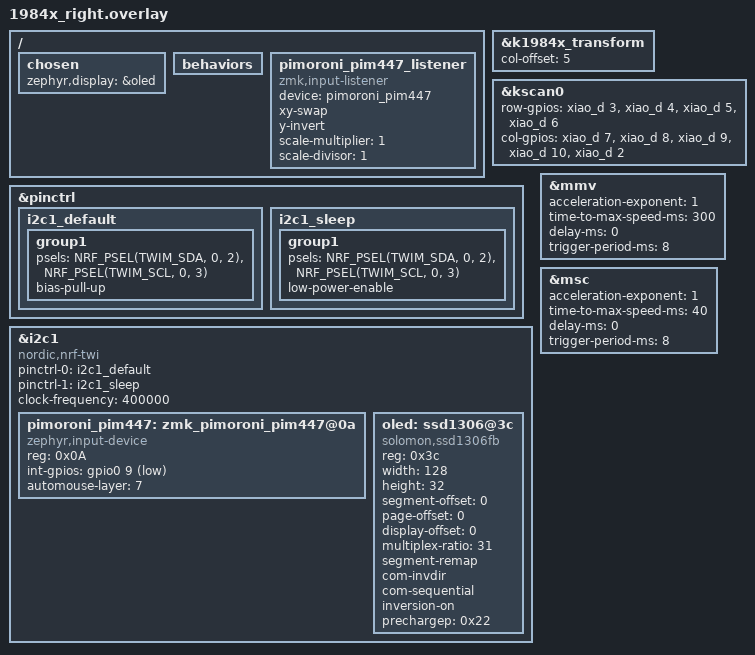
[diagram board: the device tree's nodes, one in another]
#include "1984x.dtsi"


#define ZMK_MOUSE_DEFAULT_MOVE_VAL 600  // 600
#define ZMK_MOUSE_DEFAULT_SCRL_VAL 10    // 10

#include <dt-bindings/zmk/mouse.h>

#include <behaviors/mouse_keys.dtsi>
#include <behaviors/mouse_move.dtsi>

&k1984x_transform {
    col-offset = <5>;
};

&kscan0 {
    row-gpios
        = <&xiao_d 3 (GPIO_ACTIVE_HIGH | GPIO_PULL_DOWN)>
        , <&xiao_d 4 (GPIO_ACTIVE_HIGH | GPIO_PULL_DOWN)>
        , <&xiao_d 5 (GPIO_ACTIVE_HIGH | GPIO_PULL_DOWN)>
        , <&xiao_d 6 (GPIO_ACTIVE_HIGH | GPIO_PULL_DOWN)>
        ;

    col-gpios
        = <&xiao_d 7 GPIO_ACTIVE_HIGH>
        , <&xiao_d 8 GPIO_ACTIVE_HIGH>
        , <&xiao_d 9 GPIO_ACTIVE_HIGH>
        , <&xiao_d 10 GPIO_ACTIVE_HIGH>
        , <&xiao_d 2 GPIO_ACTIVE_HIGH>
        ;
};


&pinctrl {
    i2c1_default: i2c1_default {
        group1 {
            psels = <NRF_PSEL(TWIM_SDA, 0, 2)>,
                    <NRF_PSEL(TWIM_SCL, 0, 3)>;
            bias-pull-up;
        };
    };

    i2c1_sleep: i2c1_sleep {
        group1 {
            psels = <NRF_PSEL(TWIM_SDA, 0, 2)>,
                    <NRF_PSEL(TWIM_SCL, 0, 3)>;
            low-power-enable;
        };
    };
};

/ {
    chosen {
        zephyr,display = &oled;
    };
};

&i2c1 {
    status = "okay";

    compatible = "nordic,nrf-twi";
    pinctrl-0 = <&i2c1_default>;
    pinctrl-1 = <&i2c1_sleep>;
    pinctrl-names = "default", "sleep";
    clock-frequency = <400000>;

    pimoroni_pim447: zmk_pimoroni_pim447@0a {
        compatible = "zephyr,input-device", "zmk,pimoroni-pim447";
        reg = <0x0A>;
		int-gpios = <&gpio0 9 (GPIO_ACTIVE_LOW | GPIO_PULL_UP)>;
        automouse-layer = <7>;
    };

    oled: ssd1306@3c {
        compatible = "solomon,ssd1306fb";
        reg = <0x3c>;
        width = <128>;
        height = <32>;
        segment-offset = <0>;
        page-offset = <0>;
        display-offset = <0>;
        multiplex-ratio = <31>;
        segment-remap;
        com-invdir;
        com-sequential;
        inversion-on;
        prechargep = <0x22>;
    };
};

&mmv {
    acceleration-exponent = <1>;  // 1
    time-to-max-speed-ms = <300>; // 300
    delay-ms = <0>;
    trigger-period-ms = <8>;      // 16
};

&msc {
    acceleration-exponent = <1>;  // 0
    time-to-max-speed-ms = <40>;  // 300
    delay-ms = <0>;
    trigger-period-ms = <8>;      // 16
};

/ {
    behaviors {
        // mmv: mouse_move {
        //     compatible = "zmk,behavior-input-two-axis";
        //     #binding-cells = <1>;
        //     x-input-code = <INPUT_REL_X>;
        //     y-input-code = <INPUT_REL_Y>;
        //     time-to-max-speed-ms = <500>;
        //     acceleration-exponent = <1>;
        // };


    };

	pimoroni_pim447_listener {
		compatible = "zmk,input-listener";
		device = <&pimoroni_pim447>;
	    xy-swap;
        y-invert;
        scale-multiplier = <1>;
	    scale-divisor = <1>;
	};
};


